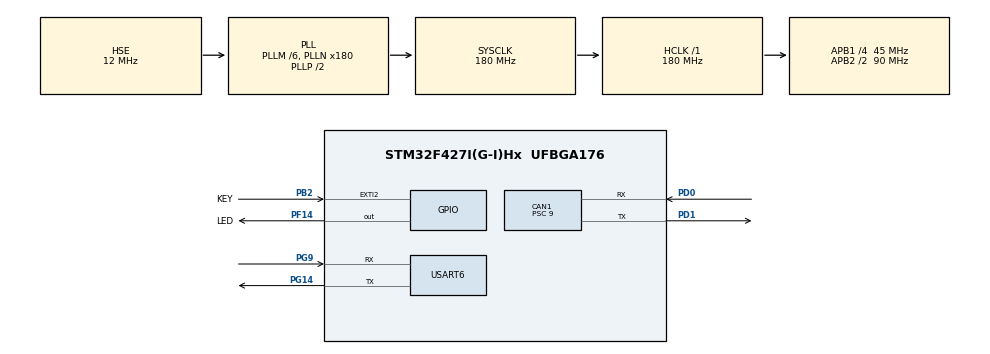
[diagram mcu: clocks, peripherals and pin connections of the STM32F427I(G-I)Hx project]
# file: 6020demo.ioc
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CAN1.BS1=CAN_BS1_3TQ
CAN1.CalculateBaudRate=1000000
CAN1.CalculateTimeBit=1000
CAN1.CalculateTimeQuantum=200.0
CAN1.Prescaler=9
Mcu.Family=STM32F4
Mcu.Name=STM32F427I(G-I)Hx
Mcu.Package=UFBGA176
NVIC.CAN1_RX0_IRQn=true\:2\:0\:true\:false\:true\:true\:true\:true
NVIC.CAN1_RX1_IRQn=true\:2\:0\:true\:false\:true\:true\:true\:true
NVIC.EXTI2_IRQn=true\:1\:0\:true\:false\:true\:true\:true\:true
NVIC.PriorityGroup=NVIC_PRIORITYGROUP_4
NVIC.TIM8_UP_TIM13_IRQn=true\:0\:0\:true\:false\:true\:false\:true\:true
NVIC.TimeBase=TIM8_UP_TIM13_IRQn
NVIC.TimeBaseIP=TIM8
NVIC.USART6_IRQn=true\:4\:0\:true\:false\:true\:true\:true\:true
PA13.Mode=Serial_Wire
PA13.Signal=SYS_JTMS-SWDIO
PA14.Mode=Serial_Wire
PA14.Signal=SYS_JTCK-SWCLK
PB2/BOOT1.GPIO_Label=KEY
PB2/BOOT1.Signal=GPXTI2
PD0.Mode=CAN_Activate
PD0.Signal=CAN1_RX
PD1.Mode=CAN_Activate
PD1.Signal=CAN1_TX
PF14.GPIO_Label=LED
PF14.Signal=GPIO_Output
PG14.Mode=Asynchronous
PG14.Signal=USART6_TX
PG9.Mode=Asynchronous
PG9.Signal=USART6_RX
PH0/OSC_IN.Mode=HSE-External-Oscillator
PH0/OSC_IN.Signal=RCC_OSC_IN
PH1/OSC_OUT.Mode=HSE-External-Oscillator
PH1/OSC_OUT.Signal=RCC_OSC_OUT
ProjectManager.HeapSize=0x200
ProjectManager.StackSize=0x400
ProjectManager.TargetToolchain=MDK-ARM V5.32
RCC.48MHZClocksFreq_Value=90000000
RCC.AHBFreq_Value=180000000
RCC.APB1CLKDivider=RCC_HCLK_DIV4
RCC.APB1Freq_Value=45000000
RCC.APB1TimFreq_Value=90000000
RCC.APB2CLKDivider=RCC_HCLK_DIV2
RCC.APB2Freq_Value=90000000
RCC.APB2TimFreq_Value=180000000
RCC.CortexFreq_Value=180000000
RCC.HCLKFreq_Value=180000000
RCC.HSE_VALUE=12000000
RCC.HSI_VALUE=16000000
RCC.LSE_VALUE=32768
RCC.PLLM=6
RCC.PLLN=180
RCC.PLLSourceVirtual=RCC_PLLSOURCE_HSE
RCC.SYSCLKFreq_VALUE=180000000
RCC.SYSCLKSource=RCC_SYSCLKSOURCE_PLLCLK
RCC.VCOOutputFreq_Value=360000000
USART6.VirtualMode=VM_ASYNC
VP_SYS_VS_tim8.Mode=TIM8
board=custom

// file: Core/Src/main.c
/* USER CODE BEGIN Header */
/**
  ******************************************************************************
  * @file           : main.c
  * @brief          : Main program body
  ******************************************************************************
  * @attention
  *
  * Copyright (c) 2025 STMicroelectronics.
  * All rights reserved.
  *
  * This software is licensed under terms that can be found in the LICENSE file
  * in the root directory of this software component.
  * If no LICENSE file comes with this software, it is provided AS-IS.
  *
  ******************************************************************************
  */
/* USER CODE END Header */
#include "main.h"
#include "can.h"
#include "usart.h"
#include "gpio.h"

/* USER CODE BEGIN Includes */
#include "bsp_can.h"
#include "GM6020.h"
#include "RobotTask.h"
#include "Key.h"
#include "DM4310.h"
/* USER CODE END Includes */

void SystemClock_Config(void);

/* USER CODE BEGIN 0 */
int fputc(int ch, FILE *f)
{
    HAL_UART_Transmit(&huart6, (uint8_t *)&ch, 1, HAL_MAX_DELAY);
    return ch;
}
void HAL_UART_RxCpltCallback(UART_HandleTypeDef *huart)
{
    if(huart->Instance == USART6)
    {

    }
}
/* USER CODE END 0 */

int main(void)
{

  /* MCU Configuration--------------------------------------------------------*/

  /* Reset of all peripherals, Initializes the Flash interface and the Systick. */
  HAL_Init();

  /* Configure the system clock */
  SystemClock_Config();

  /* Initialize all configured peripherals */
  MX_GPIO_Init();
  MX_CAN1_Init();
  MX_USART6_UART_Init();
  /* USER CODE BEGIN 2 */
  CAN_Filter_Init();
  DM4310_Init();
  // GM6020_Init();
  FreeRTOS_Start();

  /* USER CODE END 2 */

  /* Infinite loop */
  while (1)
  {

    /* USER CODE BEGIN 3 */
    // gm6020_set_current(15000);
  }
  /* USER CODE END 3 */
}

void SystemClock_Config(void)
{
  RCC_OscInitTypeDef RCC_OscInitStruct = {0};
  RCC_ClkInitTypeDef RCC_ClkInitStruct = {0};

  /** Configure the main internal regulator output voltage
  */
  __HAL_RCC_PWR_CLK_ENABLE();
  __HAL_PWR_VOLTAGESCALING_CONFIG(PWR_REGULATOR_VOLTAGE_SCALE1);

  /** Initializes the RCC Oscillators according to the specified parameters
  * in the RCC_OscInitTypeDef structure.
  */
  RCC_OscInitStruct.OscillatorType = RCC_OSCILLATORTYPE_HSE;
  RCC_OscInitStruct.HSEState = RCC_HSE_ON;
  RCC_OscInitStruct.PLL.PLLState = RCC_PLL_ON;
  RCC_OscInitStruct.PLL.PLLSource = RCC_PLLSOURCE_HSE;
  RCC_OscInitStruct.PLL.PLLM = 6;
  RCC_OscInitStruct.PLL.PLLN = 180;
  RCC_OscInitStruct.PLL.PLLP = RCC_PLLP_DIV2;
  RCC_OscInitStruct.PLL.PLLQ = 4;
  if (HAL_RCC_OscConfig(&RCC_OscInitStruct) != HAL_OK)
  {
    Error_Handler();
  }

  /** Activate the Over-Drive mode
  */
  if (HAL_PWREx_EnableOverDrive() != HAL_OK)
  {
    Error_Handler();
  }

  /** Initializes the CPU, AHB and APB buses clocks
  */
  RCC_ClkInitStruct.ClockType = RCC_CLOCKTYPE_HCLK|RCC_CLOCKTYPE_SYSCLK
                              |RCC_CLOCKTYPE_PCLK1|RCC_CLOCKTYPE_PCLK2;
  RCC_ClkInitStruct.SYSCLKSource = RCC_SYSCLKSOURCE_PLLCLK;
  RCC_ClkInitStruct.AHBCLKDivider = RCC_SYSCLK_DIV1;
  RCC_ClkInitStruct.APB1CLKDivider = RCC_HCLK_DIV4;
  RCC_ClkInitStruct.APB2CLKDivider = RCC_HCLK_DIV2;

  if (HAL_RCC_ClockConfig(&RCC_ClkInitStruct, FLASH_LATENCY_5) != HAL_OK)
  {
    Error_Handler();
  }
}

void HAL_TIM_PeriodElapsedCallback(TIM_HandleTypeDef *htim)
{
  if (htim->Instance == TIM8)
  {
    HAL_IncTick();
  }
}

void Error_Handler(void)
{
  __disable_irq();
  while (1)
  {
  }
}
